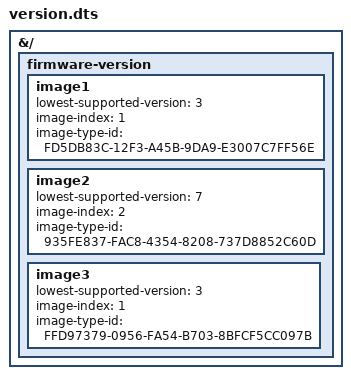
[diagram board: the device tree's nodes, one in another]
// SPDX-License-Identifier: GPL-2.0+

/dts-v1/;
/plugin/;

&{/} {
	firmware-version {
		image1 {
			lowest-supported-version = <3>;
			image-index = <1>;
			image-type-id = "FD5DB83C-12F3-A45B-9DA9-E3007C7FF56E";
		};
		image2 {
			lowest-supported-version = <7>;
			image-index = <2>;
			image-type-id = "935FE837-FAC8-4354-8208-737D8852C60D";
		};
		image3 {
			lowest-supported-version = <3>;
			image-index = <1>;
			image-type-id = "FFD97379-0956-FA54-B703-8BFCF5CC097B";
		};
	};
};
